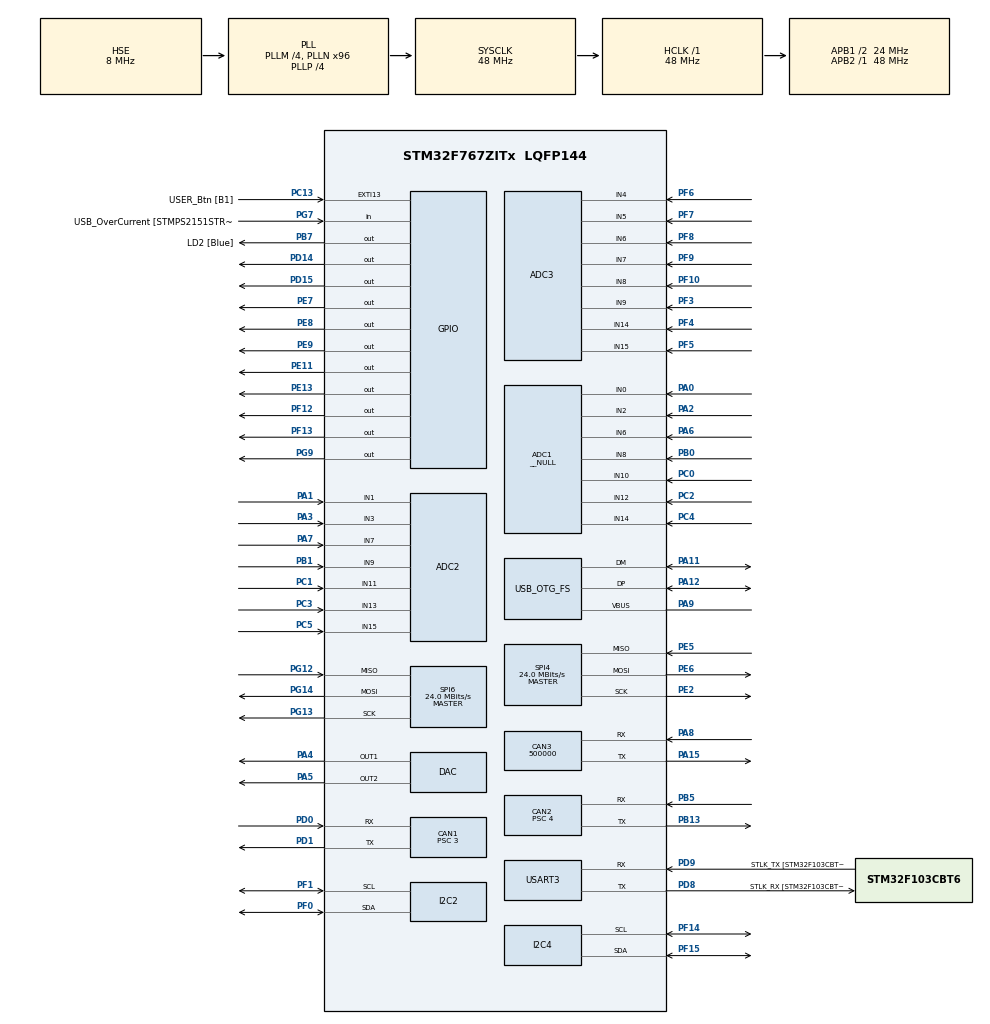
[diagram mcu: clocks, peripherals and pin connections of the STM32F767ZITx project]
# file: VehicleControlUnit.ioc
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ADC1.Channel-2\#ChannelRegularConversion=ADC_CHANNEL_0
ADC1.Channel-3\#ChannelRegularConversion=ADC_CHANNEL_2
ADC1.Channel-4\#ChannelRegularConversion=ADC_CHANNEL_6
ADC1.Channel-5\#ChannelRegularConversion=ADC_CHANNEL_8
ADC1.Channel-6\#ChannelRegularConversion=ADC_CHANNEL_10
ADC1.Channel-7\#ChannelRegularConversion=ADC_CHANNEL_12
ADC1.Channel-8\#ChannelRegularConversion=ADC_CHANNEL_12
ADC1.ClockPrescaler=ADC_CLOCK_SYNC_PCLK_DIV4
ADC1.ContinuousConvMode=DISABLE
ADC1.DMAContinuousRequests=ENABLE
ADC1.EOCSelection=ADC_EOC_SEQ_CONV
ADC1.ExternalTrigConv=ADC_EXTERNALTRIGCONV_T2_TRGO
ADC1.Mode=__NULL
ADC1.NbrOfConversion=7
ADC1.NbrOfConversionFlag=1
ADC1.Rank-2\#ChannelRegularConversion=1
ADC1.Rank-3\#ChannelRegularConversion=2
ADC1.Rank-4\#ChannelRegularConversion=3
ADC1.Rank-5\#ChannelRegularConversion=4
ADC1.Rank-6\#ChannelRegularConversion=5
ADC1.Rank-7\#ChannelRegularConversion=6
ADC1.Rank-8\#ChannelRegularConversion=7
ADC1.SamplingTime-2\#ChannelRegularConversion=ADC_SAMPLETIME_28CYCLES
ADC1.SamplingTime-3\#ChannelRegularConversion=ADC_SAMPLETIME_28CYCLES
ADC1.SamplingTime-4\#ChannelRegularConversion=ADC_SAMPLETIME_28CYCLES
ADC1.SamplingTime-5\#ChannelRegularConversion=ADC_SAMPLETIME_28CYCLES
ADC1.SamplingTime-6\#ChannelRegularConversion=ADC_SAMPLETIME_28CYCLES
ADC1.SamplingTime-7\#ChannelRegularConversion=ADC_SAMPLETIME_28CYCLES
ADC1.SamplingTime-8\#ChannelRegularConversion=ADC_SAMPLETIME_28CYCLES
ADC1.master=1
ADC2.Channel-2\#ChannelRegularConversion=ADC_CHANNEL_1
ADC2.Channel-3\#ChannelRegularConversion=ADC_CHANNEL_3
ADC2.Channel-4\#ChannelRegularConversion=ADC_CHANNEL_7
ADC2.Channel-5\#ChannelRegularConversion=ADC_CHANNEL_9
ADC2.Channel-6\#ChannelRegularConversion=ADC_CHANNEL_11
ADC2.Channel-7\#ChannelRegularConversion=ADC_CHANNEL_13
ADC2.Channel-8\#ChannelRegularConversion=ADC_CHANNEL_15
ADC2.ClockPrescaler=ADC_CLOCK_SYNC_PCLK_DIV4
ADC2.ContinuousConvMode=DISABLE
ADC2.DMAContinuousRequests=ENABLE
ADC2.EOCSelection=ADC_EOC_SEQ_CONV
ADC2.ExternalTrigConv=ADC_EXTERNALTRIGCONV_T2_TRGO
ADC2.NbrOfConversion=7
ADC2.NbrOfConversionFlag=1
ADC2.Rank-2\#ChannelRegularConversion=1
ADC2.Rank-3\#ChannelRegularConversion=2
ADC2.Rank-4\#ChannelRegularConversion=3
ADC2.Rank-5\#ChannelRegularConversion=4
ADC2.Rank-6\#ChannelRegularConversion=5
ADC2.Rank-7\#ChannelRegularConversion=6
ADC2.Rank-8\#ChannelRegularConversion=7
ADC2.SamplingTime-2\#ChannelRegularConversion=ADC_SAMPLETIME_28CYCLES
ADC2.SamplingTime-3\#ChannelRegularConversion=ADC_SAMPLETIME_28CYCLES
ADC2.SamplingTime-4\#ChannelRegularConversion=ADC_SAMPLETIME_28CYCLES
ADC2.SamplingTime-5\#ChannelRegularConversion=ADC_SAMPLETIME_28CYCLES
ADC2.SamplingTime-6\#ChannelRegularConversion=ADC_SAMPLETIME_28CYCLES
ADC2.SamplingTime-7\#ChannelRegularConversion=ADC_SAMPLETIME_28CYCLES
ADC2.SamplingTime-8\#ChannelRegularConversion=ADC_SAMPLETIME_28CYCLES
ADC3.Channel-10\#ChannelRegularConversion=ADC_CHANNEL_14
ADC3.Channel-11\#ChannelRegularConversion=ADC_CHANNEL_15
ADC3.Channel-4\#ChannelRegularConversion=ADC_CHANNEL_4
ADC3.Channel-5\#ChannelRegularConversion=ADC_CHANNEL_5
ADC3.Channel-6\#ChannelRegularConversion=ADC_CHANNEL_6
ADC3.Channel-7\#ChannelRegularConversion=ADC_CHANNEL_7
ADC3.Channel-8\#ChannelRegularConversion=ADC_CHANNEL_8
ADC3.Channel-9\#ChannelRegularConversion=ADC_CHANNEL_9
ADC3.ClockPrescaler=ADC_CLOCK_SYNC_PCLK_DIV4
ADC3.DMAContinuousRequests=ENABLE
ADC3.ExternalTrigConv=ADC_EXTERNALTRIGCONV_T2_TRGO
ADC3.NbrOfConversion=8
ADC3.NbrOfConversionFlag=1
ADC3.Rank-10\#ChannelRegularConversion=7
ADC3.Rank-11\#ChannelRegularConversion=8
ADC3.Rank-4\#ChannelRegularConversion=1
ADC3.Rank-5\#ChannelRegularConversion=2
ADC3.Rank-6\#ChannelRegularConversion=3
ADC3.Rank-7\#ChannelRegularConversion=4
ADC3.Rank-8\#ChannelRegularConversion=5
ADC3.Rank-9\#ChannelRegularConversion=6
ADC3.SamplingTime-10\#ChannelRegularConversion=ADC_SAMPLETIME_28CYCLES
ADC3.SamplingTime-11\#ChannelRegularConversion=ADC_SAMPLETIME_28CYCLES
ADC3.SamplingTime-4\#ChannelRegularConversion=ADC_SAMPLETIME_28CYCLES
ADC3.SamplingTime-5\#ChannelRegularConversion=ADC_SAMPLETIME_28CYCLES
ADC3.SamplingTime-6\#ChannelRegularConversion=ADC_SAMPLETIME_28CYCLES
ADC3.SamplingTime-7\#ChannelRegularConversion=ADC_SAMPLETIME_28CYCLES
ADC3.SamplingTime-8\#ChannelRegularConversion=ADC_SAMPLETIME_28CYCLES
ADC3.SamplingTime-9\#ChannelRegularConversion=ADC_SAMPLETIME_28CYCLES
CAN1.BS1=CAN_BS1_13TQ
CAN1.BS2=CAN_BS2_2TQ
CAN1.CalculateBaudRate=500000
CAN1.CalculateTimeBit=2000
CAN1.CalculateTimeQuantum=125.0
CAN1.Prescaler=3
CAN2.BS1=CAN_BS1_10TQ
CAN2.CalculateBaudRate=500000
CAN2.CalculateTimeBit=2000
CAN2.CalculateTimeQuantum=166.66666666666666
CAN2.Prescaler=4
CAN3.CalculateBaudRate=500000
CAN3.CalculateTimeBit=2000
CAN3.CalculateTimeQuantum=666.6666666666666
CORTEX_M7.CPU_DCache=Disabled
CORTEX_M7.CPU_ICache=Disabled
DAC.DAC_Trigger=DAC_TRIGGER_T2_TRGO
DAC.DAC_Trigger2=DAC_TRIGGER_T2_TRGO
Dma.ADC1.0.Direction=DMA_PERIPH_TO_MEMORY
Dma.ADC1.0.FIFOMode=DMA_FIFOMODE_DISABLE
Dma.ADC1.0.Instance=DMA2_Stream0
Dma.ADC1.0.MemDataAlignment=DMA_MDATAALIGN_WORD
Dma.ADC1.0.MemInc=DMA_MINC_ENABLE
Dma.ADC1.0.Mode=DMA_CIRCULAR
Dma.ADC1.0.PeriphDataAlignment=DMA_PDATAALIGN_WORD
Dma.ADC1.0.PeriphInc=DMA_PINC_DISABLE
Dma.ADC1.0.Priority=DMA_PRIORITY_LOW
Dma.ADC2.1.Direction=DMA_PERIPH_TO_MEMORY
Dma.ADC2.1.FIFOMode=DMA_FIFOMODE_DISABLE
Dma.ADC2.1.Instance=DMA2_Stream2
Dma.ADC2.1.MemDataAlignment=DMA_MDATAALIGN_WORD
Dma.ADC2.1.MemInc=DMA_MINC_ENABLE
Dma.ADC2.1.Mode=DMA_CIRCULAR
Dma.ADC2.1.PeriphDataAlignment=DMA_PDATAALIGN_WORD
Dma.ADC2.1.PeriphInc=DMA_PINC_DISABLE
Dma.ADC2.1.Priority=DMA_PRIORITY_LOW
Dma.ADC3.2.Direction=DMA_PERIPH_TO_MEMORY
Dma.ADC3.2.FIFOMode=DMA_FIFOMODE_DISABLE
Dma.ADC3.2.Instance=DMA2_Stream1
Dma.ADC3.2.MemDataAlignment=DMA_MDATAALIGN_WORD
Dma.ADC3.2.MemInc=DMA_MINC_ENABLE
Dma.ADC3.2.Mode=DMA_CIRCULAR
Dma.ADC3.2.PeriphDataAlignment=DMA_PDATAALIGN_WORD
Dma.ADC3.2.PeriphInc=DMA_PINC_DISABLE
Dma.ADC3.2.Priority=DMA_PRIORITY_LOW
Dma.DAC1.3.Direction=DMA_MEMORY_TO_PERIPH
Dma.DAC1.3.FIFOMode=DMA_FIFOMODE_DISABLE
Dma.DAC1.3.Instance=DMA1_Stream5
Dma.DAC1.3.MemDataAlignment=DMA_MDATAALIGN_HALFWORD
Dma.DAC1.3.MemInc=DMA_MINC_ENABLE
Dma.DAC1.3.Mode=DMA_CIRCULAR
Dma.DAC1.3.PeriphDataAlignment=DMA_PDATAALIGN_HALFWORD
Dma.DAC1.3.PeriphInc=DMA_PINC_DISABLE
Dma.DAC1.3.Priority=DMA_PRIORITY_LOW
Dma.DAC2.4.Direction=DMA_MEMORY_TO_PERIPH
Dma.DAC2.4.FIFOMode=DMA_FIFOMODE_DISABLE
Dma.DAC2.4.Instance=DMA1_Stream6
Dma.DAC2.4.MemDataAlignment=DMA_MDATAALIGN_HALFWORD
Dma.DAC2.4.MemInc=DMA_MINC_ENABLE
Dma.DAC2.4.Mode=DMA_CIRCULAR
Dma.DAC2.4.PeriphDataAlignment=DMA_PDATAALIGN_HALFWORD
Dma.DAC2.4.PeriphInc=DMA_PINC_DISABLE
Dma.DAC2.4.Priority=DMA_PRIORITY_LOW
Dma.Request0=ADC1
Dma.Request1=ADC2
Dma.Request2=ADC3
Dma.Request3=DAC1
Dma.Request4=DAC2
FREERTOS.Tasks01=defaultTask,24,128,StartDefaultTask,Default,NULL,Dynamic,NULL,NULL
I2C2.Timing=0x00506682
I2C4.Timing=0x00506682
Mcu.Family=STM32F7
Mcu.Name=STM32F767ZITx
Mcu.Package=LQFP144
NVIC.CAN1_RX0_IRQn=true\:5\:0\:false\:false\:true\:true\:true\:true\:true
NVIC.CAN2_RX0_IRQn=true\:5\:0\:false\:false\:true\:true\:true\:true\:true
NVIC.DMA1_Stream5_IRQn=true\:5\:0\:false\:false\:true\:true\:false\:true\:true
NVIC.DMA1_Stream6_IRQn=true\:5\:0\:false\:false\:true\:true\:false\:true\:true
NVIC.DMA2_Stream0_IRQn=true\:5\:0\:false\:false\:true\:true\:false\:true\:true
NVIC.DMA2_Stream1_IRQn=true\:5\:0\:false\:false\:true\:true\:false\:true\:true
NVIC.DMA2_Stream2_IRQn=true\:5\:0\:false\:false\:true\:true\:false\:true\:true
NVIC.OTG_FS_IRQn=true\:5\:0\:false\:false\:true\:true\:false\:true\:true
NVIC.PriorityGroup=NVIC_PRIORITYGROUP_4
NVIC.TIM2_IRQn=true\:5\:0\:false\:false\:true\:true\:true\:true\:true
NVIC.USART3_IRQn=true\:5\:0\:false\:false\:true\:true\:true\:true\:true
PA0/WKUP.Signal=ADCx_IN0
PA1.Signal=ADCx_IN1
PA11.Mode=Device_Only
PA11.Signal=USB_OTG_FS_DM
PA12.Mode=Device_Only
PA12.Signal=USB_OTG_FS_DP
PA13.GPIO_Label=TMS
PA13.Mode=Trace_Asynchronous_SW
PA13.Signal=SYS_JTMS-SWDIO
PA14.GPIO_Label=TCK
PA14.Mode=Trace_Asynchronous_SW
PA14.Signal=SYS_JTCK-SWCLK
PA15.Mode=CAN_Activate
PA15.Signal=CAN3_TX
PA2.Signal=ADCx_IN2
PA3.Signal=ADCx_IN3
PA4.Signal=COMP_DAC1_group
PA5.Signal=COMP_DAC2_group
PA6.Signal=ADCx_IN6
PA7.Signal=ADCx_IN7
PA8.Mode=CAN_Activate
PA8.Signal=CAN3_RX
PA9.Mode=Activate_VBUS
PA9.Signal=USB_OTG_FS_VBUS
PB0.Signal=ADCx_IN8
PB1.Signal=ADCx_IN9
PB13.Mode=CAN_Activate
PB13.Signal=CAN2_TX
PB3.Mode=Trace_Asynchronous_SW
PB3.Signal=SYS_JTDO-SWO
PB5.Mode=CAN_Activate
PB5.Signal=CAN2_RX
PB7.GPIO_Label=LD2 [Blue]
PB7.Signal=GPIO_Output
PB8.Signal=SDMMC1_D4
PB9.Signal=SDMMC1_D5
PC0.Signal=ADCx_IN10
PC1.Signal=ADCx_IN11
PC10.Signal=SDMMC1_D2
PC11.Signal=SDMMC1_D3
PC12.Signal=SDMMC1_CK
PC13.GPIO_Label=USER_Btn [B1]
PC13.Signal=GPXTI13
PC14/OSC32_IN.Mode=LSE-External-Oscillator
PC14/OSC32_IN.Signal=RCC_OSC32_IN
PC15/OSC32_OUT.Mode=LSE-External-Oscillator
PC15/OSC32_OUT.Signal=RCC_OSC32_OUT
PC2.Signal=ADCx_IN12
PC3.Signal=ADCx_IN13
PC4.Signal=ADCx_IN14
PC5.Signal=ADCx_IN15
PC6.Signal=SDMMC1_D6
PC7.Signal=SDMMC1_D7
PC8.Signal=SDMMC1_D0
PC9.Signal=SDMMC1_D1
PD0.Mode=CAN_Activate
PD0.Signal=CAN1_RX
PD1.Mode=CAN_Activate
PD1.Signal=CAN1_TX
PD14.Signal=GPIO_Output
PD15.Signal=GPIO_Output
PD2.Signal=SDMMC1_CMD
PD8.GPIO_Label=STLK_RX [STM32F103CBT6_PA3]
PD8.Mode=Asynchronous
PD8.Signal=USART3_TX
PD9.GPIO_Label=STLK_TX [STM32F103CBT6_PA2]
PD9.Mode=Asynchronous
PD9.Signal=USART3_RX
PE11.Signal=GPIO_Output
PE13.Signal=GPIO_Output
PE2.Mode=Full_Duplex_Master
PE2.Signal=SPI4_SCK
PE5.Mode=Full_Duplex_Master
PE5.Signal=SPI4_MISO
PE6.Mode=Full_Duplex_Master
PE6.Signal=SPI4_MOSI
PE7.Signal=GPIO_Output
PE8.Signal=GPIO_Output
PE9.Signal=GPIO_Output
PF0.Mode=I2C
PF0.Signal=I2C2_SDA
PF1.Mode=I2C
PF1.Signal=I2C2_SCL
PF10.Mode=IN8
PF10.Signal=ADC3_IN8
PF12.Signal=GPIO_Output
PF13.Signal=GPIO_Output
PF14.Mode=I2C
PF14.Signal=I2C4_SCL
PF15.Mode=I2C
PF15.Signal=I2C4_SDA
PF3.Mode=IN9
PF3.Signal=ADC3_IN9
PF4.Mode=IN14
PF4.Signal=ADC3_IN14
PF5.Mode=IN15
PF5.Signal=ADC3_IN15
PF6.Mode=IN4
PF6.Signal=ADC3_IN4
PF7.Mode=IN5
PF7.Signal=ADC3_IN5
PF8.Mode=IN6
PF8.Signal=ADC3_IN6
PF9.Mode=IN7
PF9.Signal=ADC3_IN7
PG12.Mode=Full_Duplex_Master
PG12.Signal=SPI6_MISO
PG13.Mode=Full_Duplex_Master
PG13.Signal=SPI6_SCK
PG14.Mode=Full_Duplex_Master
PG14.Signal=SPI6_MOSI
PG7.GPIO_Label=USB_OverCurrent [STMPS2151STR_FAULT]
PG7.Signal=GPIO_Input
PG9.Signal=GPIO_Output
PH0/OSC_IN.GPIO_Label=MCO [STM32F103CBT6_PA8]
PH0/OSC_IN.Mode=HSE-External-Clock-Source
PH0/OSC_IN.Signal=RCC_OSC_IN
PH1/OSC_OUT.Mode=HSE-External-Clock-Source
PH1/OSC_OUT.Signal=RCC_OSC_OUT
ProjectManager.HeapSize=0x200
ProjectManager.StackSize=0x400
ProjectManager.TargetToolchain=STM32CubeIDE
RCC.48MHZClocksFreq_Value=24000000
RCC.AHBFreq_Value=48000000
RCC.APB1CLKDivider=RCC_HCLK_DIV2
RCC.APB1Freq_Value=24000000
RCC.APB1TimFreq_Value=48000000
RCC.APB2Freq_Value=48000000
RCC.APB2TimFreq_Value=48000000
RCC.CortexFreq_Value=48000000
RCC.HCLKFreq_Value=48000000
RCC.HSE_VALUE=8000000
RCC.HSI_VALUE=16000000
RCC.PLLM=4
RCC.PLLMUL=RCC_PLL_MUL9
RCC.PLLN=96
RCC.PLLP=RCC_PLLP_DIV4
RCC.PLLQ=4
RCC.PLLSourceVirtual=RCC_PLLSOURCE_HSE
RCC.PRESCALERUSB=RCC_USBCLKSOURCE_PLL_DIV1_5
RCC.SYSCLKFreq_VALUE=48000000
RCC.SYSCLKSource=RCC_SYSCLKSOURCE_PLLCLK
RCC.SYSCLKSourceVirtual=RCC_SYSCLKSOURCE_PLLCLK
RCC.USBFreq_Value=48000000
RCC.VCOOutputFreq_Value=192000000
SH.ADCx_IN0.0=ADC1_IN0,IN0
SH.ADCx_IN1.0=ADC2_IN1,IN1
SH.ADCx_IN10.0=ADC1_IN10,IN10
SH.ADCx_IN11.0=ADC2_IN11,IN11
SH.ADCx_IN12.0=ADC1_IN12,IN12
SH.ADCx_IN13.0=ADC2_IN13,IN13
SH.ADCx_IN14.0=ADC1_IN14,IN14
SH.ADCx_IN15.0=ADC2_IN15,IN15
SH.ADCx_IN2.0=ADC1_IN2,IN2
SH.ADCx_IN3.0=ADC2_IN3,IN3
SH.ADCx_IN6.0=ADC1_IN6,IN6
SH.ADCx_IN7.0=ADC2_IN7,IN7
SH.ADCx_IN8.0=ADC1_IN8,IN8
SH.ADCx_IN9.0=ADC2_IN9,IN9
SH.COMP_DAC1_group.0=DAC_OUT1,DAC_OUT1
SH.COMP_DAC2_group.0=DAC_OUT2,DAC_OUT2
SPI4.CalculateBaudRate=24.0 MBits/s
SPI4.Direction=SPI_DIRECTION_2LINES
SPI4.Mode=SPI_MODE_MASTER
SPI4.VirtualType=VM_MASTER
SPI6.CalculateBaudRate=24.0 MBits/s
SPI6.Direction=SPI_DIRECTION_2LINES
SPI6.Mode=SPI_MODE_MASTER
SPI6.VirtualType=VM_MASTER
TIM1.Period=999
TIM1.Prescaler=47999
TIM2.Period=479999
TIM2.Prescaler=0
TIM2.TIM_MasterOutputTrigger=TIM_TRGO_UPDATE
USART3.VirtualMode-Asynchronous=VM_ASYNC
USB_DEVICE.CLASS_NAME_FS=CDC
USB_DEVICE.VirtualMode-CDC_FS=Cdc
USB_DEVICE.VirtualModeFS=Cdc_FS
USB_OTG_FS.VirtualMode=Device_Only
VP_FREERTOS_VS_CMSIS_V2.Mode=CMSIS_V2
VP_TIM1_VS_ClockSourceINT.Mode=Internal
VP_TIM2_VS_ClockSourceINT.Mode=Internal
VP_USB_DEVICE_VS_USB_DEVICE_CDC_FS.Mode=CDC_FS
board=NUCLEO-F767ZI

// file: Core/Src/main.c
/* USER CODE BEGIN Header */
/**
  ******************************************************************************
  * @file           : main.c
  * @brief          : Main program body
  ******************************************************************************
  * @attention
  *
  * Copyright (c) 2024 STMicroelectronics.
  * All rights reserved.
  *
  * This software is licensed under terms that can be found in the LICENSE file
  * in the root directory of this software component.
  * If no LICENSE file comes with this software, it is provided AS-IS.
  *
  ******************************************************************************
  */
/* USER CODE END Header */
#include "main.h"
#include "cmsis_os.h"
#include "usb_device.h"

/* USER CODE BEGIN Includes */
#include "../Inc/Files/can1_dbc.h"
#define INVERTER_TEST_DBC_IMPLEMENTATION  // Define DBC data in this file only
#include "../Inc/Files/inverter_test_dbc.h"

#define CANBUS_1_DBC_IMPLEMENTATION  // Define DBC data in this file only
#include "../Inc/Files/canbus_1_dbc.h"
#include "../Inc/Scheduler/Scheduler.h"
#include "../Inc/Sensors/AnalogSensor.h"
#include "../Inc/Systems/Comms/Can/Can.h"
#include "../Inc/Systems/Comms/Can/CANCommsSystem.h"
#include "../Inc/Systems/Controller/Apps.h"
#include "../Inc/Systems/Controller/BrakeSystemControl.h"
#include "../Inc/Systems/Controller/RTD.h"
#include "../Inc/Systems/Controller/TorqueControl.h"
#include "../Inc/Systems/External/Inverter.h"
#include "../Inc/Systems/Monitor/AppsMonitor.h"
#include "../Inc/Systems/Monitor/BrakePolice.h"
#include "../Inc/Systems/Monitor/RTDMonitor.h"
#include "../Inc/Systems/Monitor/TorquePolice.h"
#include "../Inc/Utils/Constants.h"
#include "../Inc/Utils/MessageFormat.h"
#include "../Inc/Utils/Telemetry.h"

#ifndef TEST_MODE
#include "stm32f7xx_hal_adc.h"
#include "stm32f7xx_it.h"
#endif
/* USER CODE END Includes */

/* USER CODE BEGIN PM */
#ifndef TEST_MODE
/* USER CODE END PM */

ADC_HandleTypeDef hadc1;
ADC_HandleTypeDef hadc2;
ADC_HandleTypeDef hadc3;
DMA_HandleTypeDef hdma_adc1;
DMA_HandleTypeDef hdma_adc2;
DMA_HandleTypeDef hdma_adc3;

CAN_HandleTypeDef hcan1;
CAN_HandleTypeDef hcan2;
CAN_HandleTypeDef hcan3;

DAC_HandleTypeDef hdac;
DMA_HandleTypeDef hdma_dac1;
DMA_HandleTypeDef hdma_dac2;
DMA_HandleTypeDef hdma_usart3_tx;

I2C_HandleTypeDef hi2c2;
I2C_HandleTypeDef hi2c4;

SPI_HandleTypeDef hspi4;
SPI_HandleTypeDef hspi6;

TIM_HandleTypeDef htim1;
TIM_HandleTypeDef htim2;

UART_HandleTypeDef huart3;

/* Definitions for defaultTask */
osThreadId_t defaultTaskHandle;
const osThreadAttr_t defaultTask_attributes = {
  .name = "defaultTask",
  .stack_size = 128 * 4,
  .priority = (osPriority_t) osPriorityNormal,
};
/* USER CODE BEGIN PV */
// New CAN Communications Systems (alongside existing CAN)
CANCommsSystem can1_comms;
CANCommsSystem can2_comms;
Updateable telemetryUpdateable;
/* USER CODE END PV */

void SystemClock_Config(void);
static void MX_GPIO_Init(void);
static void MX_DMA_Init(void);
static void MX_TIM1_Init(void);
static void MX_ADC1_Init(void);
static void MX_ADC2_Init(void);
static void MX_ADC3_Init(void);
static void MX_CAN1_Init(void);
static void MX_CAN2_Init(void);
static void MX_USART3_UART_Init(void);
static void MX_TIM2_Init(void);
static void MX_DAC_Init(void);
static void MX_CAN3_Init(void);
static void MX_I2C2_Init(void);
static void MX_I2C4_Init(void);
static void MX_SPI4_Init(void);
static void MX_SPI6_Init(void);
void StartDefaultTask(void *argument);

/* USER CODE BEGIN PFP */
// CAN message handler for Inverter system
//void inverter_can_handler(void* system, CAN_Message* message);
void send_test_inverter_messages(void);

// UART configuration listener
void initUartConfigListener(void);
int telemetryUpdateableCallback(Updateable* self);
#endif
/* USER CODE END PFP */

/* USER CODE BEGIN 0 */
uint32_t adc1_buffer[ADC1_CHANNEL_SIZE];
uint32_t adc2_buffer[ADC2_CHANNEL_SIZE];
uint32_t adc3_buffer[ADC3_CHANNEL_SIZE];
uint32_t dac1_buffer[DAC1_BUFFER_SIZE];
uint32_t dac2_buffer[DAC2_BUFFER_SIZE];
uint8_t digital_out_buffer[NUM_DIGITAL_OUTPUTS];
uint8_t digital_in_buffer[NUM_DIGITAL_INPUTS];

/* USER CODE END 0 */

int main(void)
{

  /* USER CODE BEGIN 1 */

  #ifndef TEST_MODE

  /* USER CODE END 1 */

  /* MCU Configuration--------------------------------------------------------*/

  /* Reset of all peripherals, Initializes the Flash interface and the Systick. */
  HAL_Init();

  /* Configure the system clock */
  SystemClock_Config();

  /* Initialize all configured peripherals */
  MX_GPIO_Init();
  MX_DMA_Init();
  MX_TIM1_Init();
  MX_ADC1_Init();
  MX_ADC2_Init();
  MX_ADC3_Init();
  MX_CAN1_Init();
  MX_CAN2_Init();
  MX_USART3_UART_Init();
  MX_TIM2_Init();
  MX_DAC_Init();
  MX_CAN3_Init();
  MX_I2C2_Init();
  MX_I2C4_Init();
  MX_SPI4_Init();
  MX_SPI6_Init();
  /* USER CODE BEGIN 2 */

  // Clear the screen
  // //printf("\033[2J\033[1;1H");
  // //printf("Welcome to VCU!!!\r\n");
  if (init_CANBus(CAN_1) != 0) {
    // //printf("CAN1 init failed\r\n");
  }

  // Init Telemetry
  initTelemetry();

  // Scheduler-based telemetry processor
  initUpdateable(&telemetryUpdateable, "TelemetrySystem", 10, SYSTEM, NULL);
  telemetryUpdateable.update = telemetryUpdateableCallback;
  telemetryUpdateable.enable(&telemetryUpdateable);

  // Initialize New CAN Communications Systems (alongside existing CAN)
  if (initCANCommsSystem(&can1_comms, "CAN1_COMMS", 10, CAN_1) != 0) {
    sendMessage("INIT", MSG_ERROR, "CANCommsSystem CAN1 initialization failed");
  } else {
    sendMessage("INIT", MSG_SYSTEM_STATUS, "CANCommsSystem CAN1 initialized successfully");

    // Load the enhanced DBC database
    if (loadCANDatabase(&can1_comms, canbus_1_dbc) != 0) {
      sendMessage("INIT", MSG_ERROR, "CAN1 DBC database load failed");
    } else {
      sendMessage("INIT", MSG_SYSTEM_STATUS, "CAN1 DBC database loaded successfully");
    }
  }

  // Initialize CAN2 system as well
  if (initCANCommsSystem(&can2_comms, "CAN2_COMMS", 10, CAN_2) != 0) {
    sendMessage("INIT", MSG_ERROR, "CANCommsSystem CAN2 initialization failed");
  } else {
    sendMessage("INIT", MSG_SYSTEM_STATUS, "CANCommsSystem CAN2 initialized successfully");

    // Load the same DBC database for CAN2 (can be different if needed)
    if (loadCANDatabase(&can2_comms, canbus_1_dbc) != 0) {
      sendMessage("INIT", MSG_ERROR, "CAN2 DBC database load failed");
    } else {
      sendMessage("INIT", MSG_SYSTEM_STATUS, "CAN2 DBC database loaded successfully");
    }
  }

  // Begin ADC DMA
  if(HAL_ADC_Start_DMA(&hadc1, (uint32_t*)adc1_buffer, 7) != HAL_OK) {
	  Error_Handler();
  }

  if(HAL_ADC_Start_DMA(&hadc2, (uint32_t*)adc2_buffer, 7) != HAL_OK) {
    Error_Handler();
  }

  if(HAL_ADC_Start_DMA(&hadc3, (uint32_t*)adc3_buffer, 8) != HAL_OK) {
    Error_Handler();
  }

  // Begin DAC DMA
  if(HAL_DAC_Start_DMA(&hdac, DAC_CHANNEL_1, (uint32_t*)dac1_buffer, DAC1_BUFFER_SIZE, DAC_ALIGN_12B_R) != HAL_OK) {
    Error_Handler();
  }

  __HAL_UART_ENABLE_IT(&huart3, UART_IT_RXNE);
  initUartConfigListener();

  uint32_t multi_mode = (ADC123_COMMON->CCR & ADC_CCR_MULTI);
  (void)multi_mode;  // Suppress unused variable warning
  //printf("ADC Multi-mode: 0x%08lX\r\n", multi_mode);

  #endif

  // Add a message to the CAN message list
  CAN_Signal_Template signals[8] = {
    { .name = "VDD", .start_bit = 0, .length = 8, .endian = 0, .isSigned = 0, .scale = 0.1, .offset = 0, .min = 0, .max = 255, .unit = "voltage", .reciever = "reciever" },
    { .name = "Char 2", .start_bit = 8, .length = 8, .endian = 0, .isSigned = 0, .scale = 1, .offset = 0, .min = 0, .max = 255, .unit = "unit", .reciever = "reciever" },
    { .name = "Char 3", .start_bit = 16, .length = 8, .endian = 0, .isSigned = 0, .scale = 1, .offset = 0, .min = 0, .max = 255, .unit = "unit", .reciever = "reciever" },
    { .name = "Char 4", .start_bit = 24, .length = 8, .endian = 0, .isSigned = 0, .scale = 1, .offset = 0, .min = 0, .max = 255, .unit = "unit", .reciever = "reciever" },
    { .name = "Char 5", .start_bit = 32, .length = 8, .endian = 0, .isSigned = 0, .scale = 1, .offset = 0, .min = 0, .max = 255, .unit = "unit", .reciever = "reciever" },
    { .name = "Char 6", .start_bit = 40, .length = 8, .endian = 0, .isSigned = 0, .scale = 1, .offset = 0, .min = 0, .max = 255, .unit = "unit", .reciever = "reciever" },
    { .name = "Char 7", .start_bit = 48, .length = 8, .endian = 0, .isSigned = 0, .scale = 1, .offset = 0, .min = 0, .max = 255, .unit = "unit", .reciever = "reciever" },
    { .name = "Char 8", .start_bit = 56, .length = 8, .endian = 0, .isSigned = 0, .scale = 1, .offset = 0, .min = 0, .max = 255, .unit = "unit", .reciever = "reciever" }
  };

  add_message_lop(CAN_1, 0x123, 8, 0, 0, "Message 1", "AD3", 8, signals);

  add_message_lop(CAN_1, 0x124, 8, 0, 0, "Message 2", "VCU", 8, signals);

  // Print the CAN message list
  print_CAN_Messages_Lists();

  uint8_t txdata[8] = {0, 1, 2, 3, 4, 5, 6, 7};
  send_CAN_message(CAN_1, CAN_2A, 124, txdata, 8);

  // Make Apps Controller and Monitor
  Apps apps;
  initApps(&apps, 10, 8, 4);

  AppsMonitor am;
  initAppsMonitor(&am, &apps, 10);

  // Bind Appsmonitor to Apps
  apps.base.addMonitor((ControllerSystem*)&apps, (MonitorSystem*)&am);

  // Start the Apps Monitor
  startAppsMonitor(&am);

  // Make Break Controller and Monitor
  BrakeSystemControl bsc;
  initBrakeSystemControl(&bsc, 10, 200, 400, 1000, 10, 5, 6, 0);

  BrakePolice bp;
  initBrakePolice(&bp, &bsc, 100, 200);

  // Bind BrakePolice to BrakeSystemControl
  bsc.base.addMonitor((ControllerSystem*)&bsc, (MonitorSystem*)&bp);

  // Start the Brake Controller and Monitor
  startBrakeSystemControl(&bsc);
  startBrakePolice(&bp);

  // Make RTD Controller and Monitor
  RTD rtd;
  initRTD(&rtd, &apps, &bsc, 10, 0, 1);

  RTDMonitor rm;
  initRTDMonitor(&rm, &rtd, 10);

  // Bind RTDMonitor to RTD
  rtd.base.addMonitor((ControllerSystem*)&rtd, (MonitorSystem*)&rm);

  // Start the RTD Controller and Monitor
  startRTD(&rtd);
  startRTDMonitor(&rm);

  // Make Inverter (Rinehart PM100DX)
  Inverter inverter;
  initInverter(&inverter, &can1_comms, 10, CAN_1, 500);  // 10Hz update, CAN1 system, CAN1 bus, 500ms heartbeat timeout

  // Register Inverter for CAN messages (VCU receives inverter status messages)
//  if (registerCANReceiver(&can1_comms, "VCU_Inverter_Ext", &inverter, inverterCANMessageHandler, EXTERNAL) == 0) {
//    sendMessage("INIT", MSG_SYSTEM_STATUS, "Rinehart PM100DX Inverter registered for CAN messages");
//  } else {
//    sendMessage("INIT", MSG_WARNING, "Failed to register Inverter for CAN messages");
//  }

  // Make Torque Controller and Monitor
  TorqueControl tc;
  initTorqueControl(&tc, &apps, 10, 240);

  // Make Scheduler from updateable array
  Scheduler scheduler;

  Updateable* updateables[9];  // Increased size to include CAN systems and telemetry
  updateables[0] = &apps.base.system.updateable;
  updateables[1] = &bsc.base.system.updateable;
  updateables[2] = &rtd.base.system.updateable;
  updateables[3] = &tc.base.system.updateable;
  updateables[4] = &inverter.base.system.updateable;
  updateables[5] = &can1_comms.base.system.updateable;  // Add CAN1 system
  updateables[6] = &can2_comms.base.system.updateable;  // Add CAN2 system
  updateables[7] = &telemetryUpdateable;
  updateables[8] = NULL;

  SchedulerInit(&scheduler, updateables);

  //printf("Starting Vehicle Control Unit with FreeRTOS scheduler...\n");

  // Start the Scheduler
  SchedulerRun(&scheduler);
  /* USER CODE END 2 */

  /* Init scheduler */
  osKernelInitialize();

  /* Create the thread(s) */
  /* creation of defaultTask */
  defaultTaskHandle = osThreadNew(StartDefaultTask, NULL, &defaultTask_attributes);

  /* Start scheduler */
  osKernelStart();

  /* We should never get here as control is now taken by the scheduler */

  /* Infinite loop */
  /* USER CODE BEGIN WHILE */
  static uint32_t test_can_counter = 0;
  while (1)
  {
    //printf("ERROR: Scheduler returned unexpectedly!\n");

    // Send test CAN message every 5 seconds
    test_can_counter++;
    if (test_can_counter >= 5) {
      test_can_counter = 0;

      // Send test CAN message with incrementing data
      uint8_t test_data[8] = {0xAA, 0xBB, 0xCC, 0xDD, (uint8_t)(HAL_GetTick() & 0xFF), 0x55, 0x66, 0x77};
      send_CAN_message(CAN_1, CAN_2A, 0x123, test_data, 8);

      // NOTE: This code never runs because SchedulerRun() blocks the main loop!

      // Send another test message with different ID
      uint8_t test_data2[8] = {0x11, 0x22, 0x33, 0x44, 0x55, 0x66, 0x77, (uint8_t)((HAL_GetTick() >> 8) & 0xFF)};
      send_CAN_message(CAN_1, CAN_2A, 0x456, test_data2, 8);
    }

    HAL_Delay(1000);
    /* USER CODE END WHILE */

    /* USER CODE BEGIN 3 */
  }
  #ifndef TEST_MODE
  /* USER CODE END 3 */
}

void SystemClock_Config(void)
{
  RCC_OscInitTypeDef RCC_OscInitStruct = {0};
  RCC_ClkInitTypeDef RCC_ClkInitStruct = {0};

  /** Configure LSE Drive Capability
  */
  HAL_PWR_EnableBkUpAccess();

  /** Configure the main internal regulator output voltage
  */
  __HAL_RCC_PWR_CLK_ENABLE();
  __HAL_PWR_VOLTAGESCALING_CONFIG(PWR_REGULATOR_VOLTAGE_SCALE3);

  /** Initializes the RCC Oscillators according to the specified parameters
  * in the RCC_OscInitTypeDef structure.
  */
  RCC_OscInitStruct.OscillatorType = RCC_OSCILLATORTYPE_HSE;
  RCC_OscInitStruct.HSEState = RCC_HSE_BYPASS;
  RCC_OscInitStruct.PLL.PLLState = RCC_PLL_ON;
  RCC_OscInitStruct.PLL.PLLSource = RCC_PLLSOURCE_HSE;
  RCC_OscInitStruct.PLL.PLLM = 4;
  RCC_OscInitStruct.PLL.PLLN = 96;
  RCC_OscInitStruct.PLL.PLLP = RCC_PLLP_DIV4;
  RCC_OscInitStruct.PLL.PLLQ = 4;
  RCC_OscInitStruct.PLL.PLLR = 2;
  if (HAL_RCC_OscConfig(&RCC_OscInitStruct) != HAL_OK)
  {
    Error_Handler();
  }

  /** Initializes the CPU, AHB and APB buses clocks
  */
  RCC_ClkInitStruct.ClockType = RCC_CLOCKTYPE_HCLK|RCC_CLOCKTYPE_SYSCLK
                              |RCC_CLOCKTYPE_PCLK1|RCC_CLOCKTYPE_PCLK2;
  RCC_ClkInitStruct.SYSCLKSource = RCC_SYSCLKSOURCE_PLLCLK;
  RCC_ClkInitStruct.AHBCLKDivider = RCC_SYSCLK_DIV1;
  RCC_ClkInitStruct.APB1CLKDivider = RCC_HCLK_DIV2;
  RCC_ClkInitStruct.APB2CLKDivider = RCC_HCLK_DIV1;

  if (HAL_RCC_ClockConfig(&RCC_ClkInitStruct, FLASH_LATENCY_1) != HAL_OK)
  {
    Error_Handler();
  }
}

static void MX_ADC1_Init(void)
{

  ADC_ChannelConfTypeDef sConfig = {0};

  /** Configure the global features of the ADC (Clock, Resolution, Data Alignment and number of conversion)
  */
  hadc1.Instance = ADC1;
  hadc1.Init.ClockPrescaler = ADC_CLOCK_SYNC_PCLK_DIV4;
  hadc1.Init.Resolution = ADC_RESOLUTION_12B;
  hadc1.Init.ScanConvMode = ADC_SCAN_ENABLE;
  hadc1.Init.ContinuousConvMode = DISABLE;
  hadc1.Init.DiscontinuousConvMode = DISABLE;
  hadc1.Init.ExternalTrigConvEdge = ADC_EXTERNALTRIGCONVEDGE_RISING;
  hadc1.Init.ExternalTrigConv = ADC_EXTERNALTRIGCONV_T2_TRGO;
  hadc1.Init.DataAlign = ADC_DATAALIGN_RIGHT;
  hadc1.Init.NbrOfConversion = 7;
  hadc1.Init.DMAContinuousRequests = ENABLE;
  hadc1.Init.EOCSelection = ADC_EOC_SEQ_CONV;
  if (HAL_ADC_Init(&hadc1) != HAL_OK)
  {
    Error_Handler();
  }

  /** Configure for the selected ADC regular channel its corresponding rank in the sequencer and its sample time.
  */
  sConfig.Channel = ADC_CHANNEL_0;
  sConfig.Rank = ADC_REGULAR_RANK_1;
  sConfig.SamplingTime = ADC_SAMPLETIME_28CYCLES;
  if (HAL_ADC_ConfigChannel(&hadc1, &sConfig) != HAL_OK)
  {
    Error_Handler();
  }

  /** Configure for the selected ADC regular channel its corresponding rank in the sequencer and its sample time.
  */
  sConfig.Channel = ADC_CHANNEL_2;
  sConfig.Rank = ADC_REGULAR_RANK_2;
  if (HAL_ADC_ConfigChannel(&hadc1, &sConfig) != HAL_OK)
  {
    Error_Handler();
  }

  /** Configure for the selected ADC regular channel its corresponding rank in the sequencer and its sample time.
  */
  sConfig.Channel = ADC_CHANNEL_6;
  sConfig.Rank = ADC_REGULAR_RANK_3;
  if (HAL_ADC_ConfigChannel(&hadc1, &sConfig) != HAL_OK)
  {
    Error_Handler();
  }

  /** Configure for the selected ADC regular channel its corresponding rank in the sequencer and its sample time.
  */
  sConfig.Channel = ADC_CHANNEL_8;
  sConfig.Rank = ADC_REGULAR_RANK_4;
  if (HAL_ADC_ConfigChannel(&hadc1, &sConfig) != HAL_OK)
  {
    Error_Handler();
  }

  /** Configure for the selected ADC regular channel its corresponding rank in the sequencer and its sample time.
  */
  sConfig.Channel = ADC_CHANNEL_10;
  sConfig.Rank = ADC_REGULAR_RANK_5;
  if (HAL_ADC_ConfigChannel(&hadc1, &sConfig) != HAL_OK)
  {
    Error_Handler();
  }

  /** Configure for the selected ADC regular channel its corresponding rank in the sequencer and its sample time.
  */
  sConfig.Channel = ADC_CHANNEL_12;
  sConfig.Rank = ADC_REGULAR_RANK_6;
  if (HAL_ADC_ConfigChannel(&hadc1, &sConfig) != HAL_OK)
  {
    Error_Handler();
  }

  /** Configure for the selected ADC regular channel its corresponding rank in the sequencer and its sample time.
  */
  sConfig.Rank = ADC_REGULAR_RANK_7;
  if (HAL_ADC_ConfigChannel(&hadc1, &sConfig) != HAL_OK)
  {
    Error_Handler();
  }

}

static void MX_ADC2_Init(void)
{

  ADC_ChannelConfTypeDef sConfig = {0};

  /** Configure the global features of the ADC (Clock, Resolution, Data Alignment and number of conversion)
  */
  hadc2.Instance = ADC2;
  hadc2.Init.ClockPrescaler = ADC_CLOCK_SYNC_PCLK_DIV4;
  hadc2.Init.Resolution = ADC_RESOLUTION_12B;
  hadc2.Init.ScanConvMode = ADC_SCAN_ENABLE;
  hadc2.Init.ContinuousConvMode = DISABLE;
  hadc2.Init.DiscontinuousConvMode = DISABLE;
  hadc2.Init.ExternalTrigConvEdge = ADC_EXTERNALTRIGCONVEDGE_RISING;
  hadc2.Init.ExternalTrigConv = ADC_EXTERNALTRIGCONV_T2_TRGO;
  hadc2.Init.DataAlign = ADC_DATAALIGN_RIGHT;
  hadc2.Init.NbrOfConversion = 7;
  hadc2.Init.DMAContinuousRequests = ENABLE;
  hadc2.Init.EOCSelection = ADC_EOC_SEQ_CONV;
  if (HAL_ADC_Init(&hadc2) != HAL_OK)
  {
    Error_Handler();
  }

  /** Configure for the selected ADC regular channel its corresponding rank in the sequencer and its sample time.
  */
  sConfig.Channel = ADC_CHANNEL_1;
  sConfig.Rank = ADC_REGULAR_RANK_1;
  sConfig.SamplingTime = ADC_SAMPLETIME_28CYCLES;
  if (HAL_ADC_ConfigChannel(&hadc2, &sConfig) != HAL_OK)
  {
    Error_Handler();
  }

  /** Configure for the selected ADC regular channel its corresponding rank in the sequencer and its sample time.
  */
  sConfig.Channel = ADC_CHANNEL_3;
  sConfig.Rank = ADC_REGULAR_RANK_2;
  if (HAL_ADC_ConfigChannel(&hadc2, &sConfig) != HAL_OK)
  {
    Error_Handler();
  }

  /** Configure for the selected ADC regular channel its corresponding rank in the sequencer and its sample time.
  */
  sConfig.Channel = ADC_CHANNEL_7;
  sConfig.Rank = ADC_REGULAR_RANK_3;
  if (HAL_ADC_ConfigChannel(&hadc2, &sConfig) != HAL_OK)
  {
    Error_Handler();
  }

  /** Configure for the selected ADC regular channel its corresponding rank in the sequencer and its sample time.
  */
  sConfig.Channel = ADC_CHANNEL_9;
  sConfig.Rank = ADC_REGULAR_RANK_4;
  if (HAL_ADC_ConfigChannel(&hadc2, &sConfig) != HAL_OK)
  {
    Error_Handler();
  }

  /** Configure for the selected ADC regular channel its corresponding rank in the sequencer and its sample time.
  */
  sConfig.Channel = ADC_CHANNEL_11;
  sConfig.Rank = ADC_REGULAR_RANK_5;
  if (HAL_ADC_ConfigChannel(&hadc2, &sConfig) != HAL_OK)
  {
    Error_Handler();
  }

  /** Configure for the selected ADC regular channel its corresponding rank in the sequencer and its sample time.
  */
  sConfig.Channel = ADC_CHANNEL_13;
  sConfig.Rank = ADC_REGULAR_RANK_6;
  if (HAL_ADC_ConfigChannel(&hadc2, &sConfig) != HAL_OK)
  {
    Error_Handler();
  }

  /** Configure for the selected ADC regular channel its corresponding rank in the sequencer and its sample time.
  */
  sConfig.Channel = ADC_CHANNEL_15;
  sConfig.Rank = ADC_REGULAR_RANK_7;
  if (HAL_ADC_ConfigChannel(&hadc2, &sConfig) != HAL_OK)
  {
    Error_Handler();
  }

}

static void MX_ADC3_Init(void)
{

  ADC_ChannelConfTypeDef sConfig = {0};

  /** Configure the global features of the ADC (Clock, Resolution, Data Alignment and number of conversion)
  */
  hadc3.Instance = ADC3;
  hadc3.Init.ClockPrescaler = ADC_CLOCK_SYNC_PCLK_DIV4;
  hadc3.Init.Resolution = ADC_RESOLUTION_12B;
  hadc3.Init.ScanConvMode = ADC_SCAN_ENABLE;
  hadc3.Init.ContinuousConvMode = DISABLE;
  hadc3.Init.DiscontinuousConvMode = DISABLE;
  hadc3.Init.ExternalTrigConvEdge = ADC_EXTERNALTRIGCONVEDGE_RISING;
  hadc3.Init.ExternalTrigConv = ADC_EXTERNALTRIGCONV_T2_TRGO;
  hadc3.Init.DataAlign = ADC_DATAALIGN_RIGHT;
  hadc3.Init.NbrOfConversion = 8;
  hadc3.Init.DMAContinuousRequests = ENABLE;
  hadc3.Init.EOCSelection = ADC_EOC_SINGLE_CONV;
  if (HAL_ADC_Init(&hadc3) != HAL_OK)
  {
    Error_Handler();
  }

  /** Configure for the selected ADC regular channel its corresponding rank in the sequencer and its sample time.
  */
  sConfig.Channel = ADC_CHANNEL_4;
  sConfig.Rank = ADC_REGULAR_RANK_1;
  sConfig.SamplingTime = ADC_SAMPLETIME_28CYCLES;
  if (HAL_ADC_ConfigChannel(&hadc3, &sConfig) != HAL_OK)
  {
    Error_Handler();
  }

  /** Configure for the selected ADC regular channel its corresponding rank in the sequencer and its sample time.
  */
  sConfig.Channel = ADC_CHANNEL_5;
  sConfig.Rank = ADC_REGULAR_RANK_2;
  if (HAL_ADC_ConfigChannel(&hadc3, &sConfig) != HAL_OK)
  {
    Error_Handler();
  }

  /** Configure for the selected ADC regular channel its corresponding rank in the sequencer and its sample time.
  */
  sConfig.Channel = ADC_CHANNEL_6;
  sConfig.Rank = ADC_REGULAR_RANK_3;
  if (HAL_ADC_ConfigChannel(&hadc3, &sConfig) != HAL_OK)
  {
    Error_Handler();
  }

  /** Configure for the selected ADC regular channel its corresponding rank in the sequencer and its sample time.
  */
  sConfig.Channel = ADC_CHANNEL_7;
  sConfig.Rank = ADC_REGULAR_RANK_4;
  if (HAL_ADC_ConfigChannel(&hadc3, &sConfig) != HAL_OK)
  {
    Error_Handler();
  }

  /** Configure for the selected ADC regular channel its corresponding rank in the sequencer and its sample time.
  */
  sConfig.Channel = ADC_CHANNEL_8;
  sConfig.Rank = ADC_REGULAR_RANK_5;
  if (HAL_ADC_ConfigChannel(&hadc3, &sConfig) != HAL_OK)
  {
    Error_Handler();
  }

  /** Configure for the selected ADC regular channel its corresponding rank in the sequencer and its sample time.
  */
  sConfig.Channel = ADC_CHANNEL_9;
  sConfig.Rank = ADC_REGULAR_RANK_6;
  if (HAL_ADC_ConfigChannel(&hadc3, &sConfig) != HAL_OK)
  {
    Error_Handler();
  }

  /** Configure for the selected ADC regular channel its corresponding rank in the sequencer and its sample time.
  */
  sConfig.Channel = ADC_CHANNEL_14;
  sConfig.Rank = ADC_REGULAR_RANK_7;
  if (HAL_ADC_ConfigChannel(&hadc3, &sConfig) != HAL_OK)
  {
    Error_Handler();
  }

  /** Configure for the selected ADC regular channel its corresponding rank in the sequencer and its sample time.
  */
  sConfig.Channel = ADC_CHANNEL_15;
  sConfig.Rank = ADC_REGULAR_RANK_8;
  if (HAL_ADC_ConfigChannel(&hadc3, &sConfig) != HAL_OK)
  {
    Error_Handler();
  }

}

static void MX_CAN1_Init(void)
{

  hcan1.Instance = CAN1;
  hcan1.Init.Prescaler = 3;
  hcan1.Init.Mode = CAN_MODE_NORMAL;
  hcan1.Init.SyncJumpWidth = CAN_SJW_1TQ;
  hcan1.Init.TimeSeg1 = CAN_BS1_13TQ;
  hcan1.Init.TimeSeg2 = CAN_BS2_2TQ;
  hcan1.Init.TimeTriggeredMode = DISABLE;
  hcan1.Init.AutoBusOff = DISABLE;
  hcan1.Init.AutoWakeUp = DISABLE;
  hcan1.Init.AutoRetransmission = DISABLE;
  hcan1.Init.ReceiveFifoLocked = DISABLE;
  hcan1.Init.TransmitFifoPriority = DISABLE;
  if (HAL_CAN_Init(&hcan1) != HAL_OK)
  {
    Error_Handler();
  }
  /* USER CODE BEGIN CAN1_Init 2 */
  CAN_FilterTypeDef sFilterConfig;
  sFilterConfig.FilterBank = 0;
  sFilterConfig.FilterMode = CAN_FILTERMODE_IDMASK;
  sFilterConfig.FilterScale = CAN_FILTERSCALE_32BIT;
  sFilterConfig.FilterIdHigh = 0x0000;
  sFilterConfig.FilterIdLow = 0x0000;
  sFilterConfig.FilterMaskIdHigh = 0x0000;
  sFilterConfig.FilterMaskIdLow = 0x0000;
  sFilterConfig.FilterFIFOAssignment = CAN_RX_FIFO0;
  sFilterConfig.FilterActivation = ENABLE;
  sFilterConfig.SlaveStartFilterBank = 14;
  HAL_CAN_ConfigFilter(&hcan1, &sFilterConfig);

  // Stop CAN
  HAL_CAN_Stop(&hcan1);
  // Start CAN
  if (HAL_CAN_Start(&hcan1) != HAL_OK) {
      printf("CAN1 Start Error: ErrorCode = 0x%lX\r\n", hcan1.ErrorCode);
  } else {
      printf("CAN1 Started Successfully\r\n");
  }

  // Start IRQ for CAN Rx
  if (HAL_CAN_ActivateNotification(&hcan1, CAN_IT_RX_FIFO0_MSG_PENDING) != HAL_OK) {
  	printf("interrupt CAN1 init failed\r\n");
  } else {
      printf("CAN1 RX Interrupt Activated\r\n");
  }

  // Enable TX completion interrupts for telemetry
  if (HAL_CAN_ActivateNotification(&hcan1, CAN_IT_TX_MAILBOX_EMPTY) != HAL_OK) {
  	printf("CAN1 TX interrupt init failed\r\n");
  } else {
      printf("CAN1 TX Interrupt Activated\r\n");
  }
  /* USER CODE END CAN1_Init 2 */

}

static void MX_CAN2_Init(void)
{

  hcan2.Instance = CAN2;
  hcan2.Init.Prescaler = 4;
  hcan2.Init.Mode = CAN_MODE_NORMAL;
  hcan2.Init.SyncJumpWidth = CAN_SJW_1TQ;
  hcan2.Init.TimeSeg1 = CAN_BS1_10TQ;
  hcan2.Init.TimeSeg2 = CAN_BS2_1TQ;
  hcan2.Init.TimeTriggeredMode = DISABLE;
  hcan2.Init.AutoBusOff = DISABLE;
  hcan2.Init.AutoWakeUp = DISABLE;
  hcan2.Init.AutoRetransmission = DISABLE;
  hcan2.Init.ReceiveFifoLocked = DISABLE;
  hcan2.Init.TransmitFifoPriority = DISABLE;
  if (HAL_CAN_Init(&hcan2) != HAL_OK)
  {
    Error_Handler();
  }
  /* USER CODE BEGIN CAN2_Init 2 */
  CAN_FilterTypeDef sFilterConfig;
  sFilterConfig.FilterBank = 0;
  sFilterConfig.FilterMode = CAN_FILTERMODE_IDMASK;
  sFilterConfig.FilterScale = CAN_FILTERSCALE_32BIT;
  sFilterConfig.FilterIdHigh = 0x0000;
  sFilterConfig.FilterIdLow = 0x0000;
  sFilterConfig.FilterMaskIdHigh = 0x0000;
  sFilterConfig.FilterMaskIdLow = 0x0000;
  sFilterConfig.FilterFIFOAssignment = CAN_RX_FIFO0;
  sFilterConfig.FilterActivation = ENABLE;
  sFilterConfig.SlaveStartFilterBank = 14;
  HAL_CAN_ConfigFilter(&hcan2, &sFilterConfig);

  // Stop CAN
  HAL_CAN_Stop(&hcan2);
  // Start CAN
  if (HAL_CAN_Start(&hcan2) != HAL_OK) {
      //printf("CAN2 Start Error: ErrorCode = 0x%lX\r\n", hcan2.ErrorCode);
  }

  // Start IRQ for CAN Rx
  if (HAL_CAN_ActivateNotification(&hcan2, CAN_IT_RX_FIFO0_MSG_PENDING) != HAL_OK) {
  	//printf("interrupt CAN2 init failed\r\n");
  }

  // Enable TX completion interrupts for telemetry
  if (HAL_CAN_ActivateNotification(&hcan2, CAN_IT_TX_MAILBOX_EMPTY) != HAL_OK) {
  	//printf("CAN2 TX interrupt init failed\r\n");
  }
  /* USER CODE END CAN2_Init 2 */

}

static void MX_CAN3_Init(void)
{

  hcan3.Instance = CAN3;
  hcan3.Init.Prescaler = 16;
  hcan3.Init.Mode = CAN_MODE_NORMAL;
  hcan3.Init.SyncJumpWidth = CAN_SJW_1TQ;
  hcan3.Init.TimeSeg1 = CAN_BS1_1TQ;
  hcan3.Init.TimeSeg2 = CAN_BS2_1TQ;
  hcan3.Init.TimeTriggeredMode = DISABLE;
  hcan3.Init.AutoBusOff = DISABLE;
  hcan3.Init.AutoWakeUp = DISABLE;
  hcan3.Init.AutoRetransmission = DISABLE;
  hcan3.Init.ReceiveFifoLocked = DISABLE;
  hcan3.Init.TransmitFifoPriority = DISABLE;
  if (HAL_CAN_Init(&hcan3) != HAL_OK)
  {
    Error_Handler();
  }

}

static void MX_DAC_Init(void)
{

  DAC_ChannelConfTypeDef sConfig = {0};

  /** DAC Initialization
  */
  hdac.Instance = DAC;
  if (HAL_DAC_Init(&hdac) != HAL_OK)
  {
    Error_Handler();
  }

  /** DAC channel OUT1 config
  */
  sConfig.DAC_Trigger = DAC_TRIGGER_T2_TRGO;
  sConfig.DAC_OutputBuffer = DAC_OUTPUTBUFFER_ENABLE;
  if (HAL_DAC_ConfigChannel(&hdac, &sConfig, DAC_CHANNEL_1) != HAL_OK)
  {
    Error_Handler();
  }

  /** DAC channel OUT2 config
  */
  if (HAL_DAC_ConfigChannel(&hdac, &sConfig, DAC_CHANNEL_2) != HAL_OK)
  {
    Error_Handler();
  }

}

static void MX_I2C2_Init(void)
{

  hi2c2.Instance = I2C2;
  hi2c2.Init.Timing = 0x00506682;
  hi2c2.Init.OwnAddress1 = 0;
  hi2c2.Init.AddressingMode = I2C_ADDRESSINGMODE_7BIT;
  hi2c2.Init.DualAddressMode = I2C_DUALADDRESS_DISABLE;
  hi2c2.Init.OwnAddress2 = 0;
  hi2c2.Init.OwnAddress2Masks = I2C_OA2_NOMASK;
  hi2c2.Init.GeneralCallMode = I2C_GENERALCALL_DISABLE;
  hi2c2.Init.NoStretchMode = I2C_NOSTRETCH_DISABLE;
  if (HAL_I2C_Init(&hi2c2) != HAL_OK)
  {
    Error_Handler();
  }

  /** Configure Analogue filter
  */
  if (HAL_I2CEx_ConfigAnalogFilter(&hi2c2, I2C_ANALOGFILTER_ENABLE) != HAL_OK)
  {
    Error_Handler();
  }

  /** Configure Digital filter
  */
  if (HAL_I2CEx_ConfigDigitalFilter(&hi2c2, 0) != HAL_OK)
  {
    Error_Handler();
  }

}

static void MX_I2C4_Init(void)
{

  hi2c4.Instance = I2C4;
  hi2c4.Init.Timing = 0x00506682;
  hi2c4.Init.OwnAddress1 = 0;
  hi2c4.Init.AddressingMode = I2C_ADDRESSINGMODE_7BIT;
  hi2c4.Init.DualAddressMode = I2C_DUALADDRESS_DISABLE;
  hi2c4.Init.OwnAddress2 = 0;
  hi2c4.Init.OwnAddress2Masks = I2C_OA2_NOMASK;
  hi2c4.Init.GeneralCallMode = I2C_GENERALCALL_DISABLE;
  hi2c4.Init.NoStretchMode = I2C_NOSTRETCH_DISABLE;
  if (HAL_I2C_Init(&hi2c4) != HAL_OK)
  {
    Error_Handler();
  }

  /** Configure Analogue filter
  */
  if (HAL_I2CEx_ConfigAnalogFilter(&hi2c4, I2C_ANALOGFILTER_ENABLE) != HAL_OK)
  {
    Error_Handler();
  }

  /** Configure Digital filter
  */
  if (HAL_I2CEx_ConfigDigitalFilter(&hi2c4, 0) != HAL_OK)
  {
    Error_Handler();
  }

}

static void MX_SPI4_Init(void)
{

  /* SPI4 parameter configuration*/
  hspi4.Instance = SPI4;
  hspi4.Init.Mode = SPI_MODE_MASTER;
  hspi4.Init.Direction = SPI_DIRECTION_2LINES;
  hspi4.Init.DataSize = SPI_DATASIZE_4BIT;
  hspi4.Init.CLKPolarity = SPI_POLARITY_LOW;
  hspi4.Init.CLKPhase = SPI_PHASE_1EDGE;
  hspi4.Init.NSS = SPI_NSS_SOFT;
  hspi4.Init.BaudRatePrescaler = SPI_BAUDRATEPRESCALER_2;
  hspi4.Init.FirstBit = SPI_FIRSTBIT_MSB;
  hspi4.Init.TIMode = SPI_TIMODE_DISABLE;
  hspi4.Init.CRCCalculation = SPI_CRCCALCULATION_DISABLE;
  hspi4.Init.CRCPolynomial = 7;
  hspi4.Init.CRCLength = SPI_CRC_LENGTH_DATASIZE;
  hspi4.Init.NSSPMode = SPI_NSS_PULSE_ENABLE;
  if (HAL_SPI_Init(&hspi4) != HAL_OK)
  {
    Error_Handler();
  }

}

static void MX_SPI6_Init(void)
{

  /* SPI6 parameter configuration*/
  hspi6.Instance = SPI6;
  hspi6.Init.Mode = SPI_MODE_MASTER;
  hspi6.Init.Direction = SPI_DIRECTION_2LINES;
  hspi6.Init.DataSize = SPI_DATASIZE_4BIT;
  hspi6.Init.CLKPolarity = SPI_POLARITY_LOW;
  hspi6.Init.CLKPhase = SPI_PHASE_1EDGE;
  hspi6.Init.NSS = SPI_NSS_SOFT;
  hspi6.Init.BaudRatePrescaler = SPI_BAUDRATEPRESCALER_2;
  hspi6.Init.FirstBit = SPI_FIRSTBIT_MSB;
  hspi6.Init.TIMode = SPI_TIMODE_DISABLE;
  hspi6.Init.CRCCalculation = SPI_CRCCALCULATION_DISABLE;
  hspi6.Init.CRCPolynomial = 7;
  hspi6.Init.CRCLength = SPI_CRC_LENGTH_DATASIZE;
  hspi6.Init.NSSPMode = SPI_NSS_PULSE_ENABLE;
  if (HAL_SPI_Init(&hspi6) != HAL_OK)
  {
    Error_Handler();
  }

}

static void MX_TIM1_Init(void)
{

  TIM_ClockConfigTypeDef sClockSourceConfig = {0};
  TIM_MasterConfigTypeDef sMasterConfig = {0};

  htim1.Instance = TIM1;
  htim1.Init.Prescaler = 47999;
  htim1.Init.CounterMode = TIM_COUNTERMODE_UP;
  htim1.Init.Period = 999;
  htim1.Init.ClockDivision = TIM_CLOCKDIVISION_DIV1;
  htim1.Init.RepetitionCounter = 0;
  htim1.Init.AutoReloadPreload = TIM_AUTORELOAD_PRELOAD_DISABLE;
  if (HAL_TIM_Base_Init(&htim1) != HAL_OK)
  {
    Error_Handler();
  }
  sClockSourceConfig.ClockSource = TIM_CLOCKSOURCE_INTERNAL;
  if (HAL_TIM_ConfigClockSource(&htim1, &sClockSourceConfig) != HAL_OK)
  {
    Error_Handler();
  }
  sMasterConfig.MasterOutputTrigger = TIM_TRGO_RESET;
  sMasterConfig.MasterOutputTrigger2 = TIM_TRGO2_RESET;
  sMasterConfig.MasterSlaveMode = TIM_MASTERSLAVEMODE_DISABLE;
  if (HAL_TIMEx_MasterConfigSynchronization(&htim1, &sMasterConfig) != HAL_OK)
  {
    Error_Handler();
  }

}

static void MX_TIM2_Init(void)
{

  TIM_ClockConfigTypeDef sClockSourceConfig = {0};
  TIM_MasterConfigTypeDef sMasterConfig = {0};

  htim2.Instance = TIM2;
  htim2.Init.Prescaler = 0;
  htim2.Init.CounterMode = TIM_COUNTERMODE_UP;
  htim2.Init.Period = 479999;
  htim2.Init.ClockDivision = TIM_CLOCKDIVISION_DIV1;
  htim2.Init.AutoReloadPreload = TIM_AUTORELOAD_PRELOAD_DISABLE;
  if (HAL_TIM_Base_Init(&htim2) != HAL_OK)
  {
    Error_Handler();
  }
  sClockSourceConfig.ClockSource = TIM_CLOCKSOURCE_INTERNAL;
  if (HAL_TIM_ConfigClockSource(&htim2, &sClockSourceConfig) != HAL_OK)
  {
    Error_Handler();
  }
  sMasterConfig.MasterOutputTrigger = TIM_TRGO_UPDATE;
  sMasterConfig.MasterSlaveMode = TIM_MASTERSLAVEMODE_DISABLE;
  if (HAL_TIMEx_MasterConfigSynchronization(&htim2, &sMasterConfig) != HAL_OK)
  {
    Error_Handler();
  }
  /* USER CODE BEGIN TIM2_Init 2 */
  if (HAL_TIM_Base_Start_IT(&htim2) != HAL_OK) {
      Error_Handler();
  }
  /* USER CODE END TIM2_Init 2 */

}

static void MX_USART3_UART_Init(void)
{

  huart3.Instance = USART3;
  huart3.Init.BaudRate = 115200;
  huart3.Init.WordLength = UART_WORDLENGTH_8B;
  huart3.Init.StopBits = UART_STOPBITS_1;
  huart3.Init.Parity = UART_PARITY_NONE;
  huart3.Init.Mode = UART_MODE_TX_RX;
  huart3.Init.HwFlowCtl = UART_HWCONTROL_NONE;
  huart3.Init.OverSampling = UART_OVERSAMPLING_16;
  huart3.Init.OneBitSampling = UART_ONE_BIT_SAMPLE_DISABLE;
  huart3.AdvancedInit.AdvFeatureInit = UART_ADVFEATURE_NO_INIT;
  if (HAL_UART_Init(&huart3) != HAL_OK)
  {
    Error_Handler();
  }

}

static void MX_DMA_Init(void)
{

  /* DMA controller clock enable */
  __HAL_RCC_DMA2_CLK_ENABLE();
  __HAL_RCC_DMA1_CLK_ENABLE();

  /* USART3 TX DMA configuration */
  hdma_usart3_tx.Instance = DMA1_Stream3;
  hdma_usart3_tx.Init.Channel = DMA_CHANNEL_4;
  hdma_usart3_tx.Init.Direction = DMA_MEMORY_TO_PERIPH;
  hdma_usart3_tx.Init.PeriphInc = DMA_PINC_DISABLE;
  hdma_usart3_tx.Init.MemInc = DMA_MINC_ENABLE;
  hdma_usart3_tx.Init.PeriphDataAlignment = DMA_PDATAALIGN_BYTE;
  hdma_usart3_tx.Init.MemDataAlignment = DMA_MDATAALIGN_BYTE;
  hdma_usart3_tx.Init.Mode = DMA_NORMAL;
  hdma_usart3_tx.Init.Priority = DMA_PRIORITY_LOW;
  hdma_usart3_tx.Init.FIFOMode = DMA_FIFOMODE_DISABLE;
  if (HAL_DMA_Init(&hdma_usart3_tx) != HAL_OK)
  {
    Error_Handler();
  }
  __HAL_LINKDMA(&huart3, hdmatx, hdma_usart3_tx);

  /* DMA interrupt init */
  /* DMA1_Stream5_IRQn interrupt configuration */
  HAL_NVIC_SetPriority(DMA1_Stream5_IRQn, 5, 0);
  HAL_NVIC_EnableIRQ(DMA1_Stream5_IRQn);
  /* DMA1_Stream6_IRQn interrupt configuration */
  HAL_NVIC_SetPriority(DMA1_Stream6_IRQn, 5, 0);
  HAL_NVIC_EnableIRQ(DMA1_Stream6_IRQn);
  /* DMA1_Stream3_IRQn interrupt configuration */
  HAL_NVIC_SetPriority(DMA1_Stream3_IRQn, 5, 0);
  HAL_NVIC_EnableIRQ(DMA1_Stream3_IRQn);
  /* DMA2_Stream0_IRQn interrupt configuration */
  HAL_NVIC_SetPriority(DMA2_Stream0_IRQn, 5, 0);
  HAL_NVIC_EnableIRQ(DMA2_Stream0_IRQn);
  /* DMA2_Stream1_IRQn interrupt configuration */
  HAL_NVIC_SetPriority(DMA2_Stream1_IRQn, 5, 0);
  HAL_NVIC_EnableIRQ(DMA2_Stream1_IRQn);
  /* DMA2_Stream2_IRQn interrupt configuration */
  HAL_NVIC_SetPriority(DMA2_Stream2_IRQn, 5, 0);
  HAL_NVIC_EnableIRQ(DMA2_Stream2_IRQn);

}

static void MX_GPIO_Init(void)
{
  GPIO_InitTypeDef GPIO_InitStruct = {0};

  /* GPIO Ports Clock Enable */
  __HAL_RCC_GPIOE_CLK_ENABLE();
  __HAL_RCC_GPIOC_CLK_ENABLE();
  __HAL_RCC_GPIOF_CLK_ENABLE();
  __HAL_RCC_GPIOH_CLK_ENABLE();
  __HAL_RCC_GPIOA_CLK_ENABLE();
  __HAL_RCC_GPIOB_CLK_ENABLE();
  __HAL_RCC_GPIOG_CLK_ENABLE();
  __HAL_RCC_GPIOD_CLK_ENABLE();

  /*Configure GPIO pin Output Level */
  HAL_GPIO_WritePin(GPIOF, GPIO_PIN_12|GPIO_PIN_13, GPIO_PIN_RESET);

  /*Configure GPIO pin Output Level */
  HAL_GPIO_WritePin(GPIOE, GPIO_PIN_7|GPIO_PIN_8|GPIO_PIN_9|GPIO_PIN_11
                          |GPIO_PIN_13, GPIO_PIN_RESET);

  /*Configure GPIO pin Output Level */
  HAL_GPIO_WritePin(GPIOD, GPIO_PIN_14|GPIO_PIN_15, GPIO_PIN_RESET);

  /*Configure GPIO pin Output Level */
  HAL_GPIO_WritePin(GPIOG, GPIO_PIN_9, GPIO_PIN_RESET);

  /*Configure GPIO pin Output Level */
  HAL_GPIO_WritePin(LD2_GPIO_Port, LD2_Pin, GPIO_PIN_RESET);

  /*Configure GPIO pins : PE3 PE4 PE10 PE12
                           PE14 PE15 PE0 PE1 */
  GPIO_InitStruct.Pin = GPIO_PIN_3|GPIO_PIN_4|GPIO_PIN_10|GPIO_PIN_12
                          |GPIO_PIN_14|GPIO_PIN_15|GPIO_PIN_0|GPIO_PIN_1;
  GPIO_InitStruct.Mode = GPIO_MODE_ANALOG;
  GPIO_InitStruct.Pull = GPIO_NOPULL;
  HAL_GPIO_Init(GPIOE, &GPIO_InitStruct);

  /*Configure GPIO pin : USER_Btn_Pin */
  GPIO_InitStruct.Pin = USER_Btn_Pin;
  GPIO_InitStruct.Mode = GPIO_MODE_IT_RISING;
  GPIO_InitStruct.Pull = GPIO_NOPULL;
  HAL_GPIO_Init(USER_Btn_GPIO_Port, &GPIO_InitStruct);

  /*Configure GPIO pins : PF2 PF11 */
  GPIO_InitStruct.Pin = GPIO_PIN_2|GPIO_PIN_11;
  GPIO_InitStruct.Mode = GPIO_MODE_ANALOG;
  GPIO_InitStruct.Pull = GPIO_NOPULL;
  HAL_GPIO_Init(GPIOF, &GPIO_InitStruct);

  /*Configure GPIO pins : PB2 PB10 PB11 PB12
                           PB14 PB15 PB4 PB6 */
  GPIO_InitStruct.Pin = GPIO_PIN_2|GPIO_PIN_10|GPIO_PIN_11|GPIO_PIN_12
                          |GPIO_PIN_14|GPIO_PIN_15|GPIO_PIN_4|GPIO_PIN_6;
  GPIO_InitStruct.Mode = GPIO_MODE_ANALOG;
  GPIO_InitStruct.Pull = GPIO_NOPULL;
  HAL_GPIO_Init(GPIOB, &GPIO_InitStruct);

  /*Configure GPIO pins : PF12 PF13 */
  GPIO_InitStruct.Pin = GPIO_PIN_12|GPIO_PIN_13;
  GPIO_InitStruct.Mode = GPIO_MODE_OUTPUT_PP;
  GPIO_InitStruct.Pull = GPIO_NOPULL;
  GPIO_InitStruct.Speed = GPIO_SPEED_FREQ_LOW;
  HAL_GPIO_Init(GPIOF, &GPIO_InitStruct);

  /*Configure GPIO pins : PG0 PG1 PG2 PG3
                           PG4 PG5 PG6 PG8
                           PG10 PG11 PG15 */
  GPIO_InitStruct.Pin = GPIO_PIN_0|GPIO_PIN_1|GPIO_PIN_2|GPIO_PIN_3
                          |GPIO_PIN_4|GPIO_PIN_5|GPIO_PIN_6|GPIO_PIN_8
                          |GPIO_PIN_10|GPIO_PIN_11|GPIO_PIN_15;
  GPIO_InitStruct.Mode = GPIO_MODE_ANALOG;
  GPIO_InitStruct.Pull = GPIO_NOPULL;
  HAL_GPIO_Init(GPIOG, &GPIO_InitStruct);

  /*Configure GPIO pins : PE7 PE8 PE9 PE11
                           PE13 */
  GPIO_InitStruct.Pin = GPIO_PIN_7|GPIO_PIN_8|GPIO_PIN_9|GPIO_PIN_11
                          |GPIO_PIN_13;
  GPIO_InitStruct.Mode = GPIO_MODE_OUTPUT_PP;
  GPIO_InitStruct.Pull = GPIO_NOPULL;
  GPIO_InitStruct.Speed = GPIO_SPEED_FREQ_LOW;
  HAL_GPIO_Init(GPIOE, &GPIO_InitStruct);

  /*Configure GPIO pins : PD10 PD11 PD12 PD13
                           PD3 PD4 PD5 PD6
                           PD7 */
  GPIO_InitStruct.Pin = GPIO_PIN_10|GPIO_PIN_11|GPIO_PIN_12|GPIO_PIN_13
                          |GPIO_PIN_3|GPIO_PIN_4|GPIO_PIN_5|GPIO_PIN_6
                          |GPIO_PIN_7;
  GPIO_InitStruct.Mode = GPIO_MODE_ANALOG;
  GPIO_InitStruct.Pull = GPIO_NOPULL;
  HAL_GPIO_Init(GPIOD, &GPIO_InitStruct);

  /*Configure GPIO pins : PD14 PD15 */
  GPIO_InitStruct.Pin = GPIO_PIN_14|GPIO_PIN_15;
  GPIO_InitStruct.Mode = GPIO_MODE_OUTPUT_PP;
  GPIO_InitStruct.Pull = GPIO_NOPULL;
  GPIO_InitStruct.Speed = GPIO_SPEED_FREQ_LOW;
  HAL_GPIO_Init(GPIOD, &GPIO_InitStruct);

  /*Configure GPIO pin : USB_OverCurrent_Pin */
  GPIO_InitStruct.Pin = USB_OverCurrent_Pin;
  GPIO_InitStruct.Mode = GPIO_MODE_INPUT;
  GPIO_InitStruct.Pull = GPIO_NOPULL;
  HAL_GPIO_Init(USB_OverCurrent_GPIO_Port, &GPIO_InitStruct);

  /*Configure GPIO pins : PC6 PC7 PC8 PC9
                           PC10 PC11 PC12 */
  GPIO_InitStruct.Pin = GPIO_PIN_6|GPIO_PIN_7|GPIO_PIN_8|GPIO_PIN_9
                          |GPIO_PIN_10|GPIO_PIN_11|GPIO_PIN_12;
  GPIO_InitStruct.Mode = GPIO_MODE_AF_PP;
  GPIO_InitStruct.Pull = GPIO_NOPULL;
  GPIO_InitStruct.Speed = GPIO_SPEED_FREQ_VERY_HIGH;
  GPIO_InitStruct.Alternate = GPIO_AF12_SDMMC1;
  HAL_GPIO_Init(GPIOC, &GPIO_InitStruct);

  /*Configure GPIO pin : PA10 */
  GPIO_InitStruct.Pin = GPIO_PIN_10;
  GPIO_InitStruct.Mode = GPIO_MODE_ANALOG;
  GPIO_InitStruct.Pull = GPIO_NOPULL;
  HAL_GPIO_Init(GPIOA, &GPIO_InitStruct);

  /*Configure GPIO pin : PD2 */
  GPIO_InitStruct.Pin = GPIO_PIN_2;
  GPIO_InitStruct.Mode = GPIO_MODE_AF_PP;
  GPIO_InitStruct.Pull = GPIO_NOPULL;
  GPIO_InitStruct.Speed = GPIO_SPEED_FREQ_VERY_HIGH;
  GPIO_InitStruct.Alternate = GPIO_AF12_SDMMC1;
  HAL_GPIO_Init(GPIOD, &GPIO_InitStruct);

  /*Configure GPIO pin : PG9 */
  GPIO_InitStruct.Pin = GPIO_PIN_9;
  GPIO_InitStruct.Mode = GPIO_MODE_OUTPUT_PP;
  GPIO_InitStruct.Pull = GPIO_NOPULL;
  GPIO_InitStruct.Speed = GPIO_SPEED_FREQ_LOW;
  HAL_GPIO_Init(GPIOG, &GPIO_InitStruct);

  /*Configure GPIO pin : LD2_Pin */
  GPIO_InitStruct.Pin = LD2_Pin;
  GPIO_InitStruct.Mode = GPIO_MODE_OUTPUT_PP;
  GPIO_InitStruct.Pull = GPIO_NOPULL;
  GPIO_InitStruct.Speed = GPIO_SPEED_FREQ_LOW;
  HAL_GPIO_Init(LD2_GPIO_Port, &GPIO_InitStruct);

  /*Configure GPIO pins : PB8 PB9 */
  GPIO_InitStruct.Pin = GPIO_PIN_8|GPIO_PIN_9;
  GPIO_InitStruct.Mode = GPIO_MODE_AF_PP;
  GPIO_InitStruct.Pull = GPIO_NOPULL;
  GPIO_InitStruct.Speed = GPIO_SPEED_FREQ_VERY_HIGH;
  GPIO_InitStruct.Alternate = GPIO_AF12_SDMMC1;
  HAL_GPIO_Init(GPIOB, &GPIO_InitStruct);

}

/* USER CODE BEGIN 4 */
// Override the _write function to reroute printf to USART3
int _write(int file, char *data, int len)
{
    // Transmit data using the non-blocking UART DMA queue.
    // This keeps printf from blocking the scheduler.
    if (sendMessageRaw(data, len) > 0) {
        return len;
    }

    return 0;
}

int telemetryUpdateableCallback(Updateable* self)
{
    (void)self;
    processTelemetryConfigRequests();
    processTelemetrySignals();
    return 0;
}

#endif // <--- DONT DELETE THIS, IT IS LINKED TO LAST LINE IN MAIN FUNCTION TO ALLOW SIL BUILDS

/* FreeRTOS hooks */
void vApplicationMallocFailedHook(void) {
    //printf("ERROR: FreeRTOS malloc failed!\n");
    for(;;);
}

void vApplicationIdleHook(void) {
    // Called when no tasks are running
    // Can enter low power mode here
}

void vApplicationStackOverflowHook(TaskHandle_t xTask, char *pcTaskName) {
    //printf("ERROR: Stack overflow in task: %s\n", pcTaskName);
    for(;;);
}

void vApplicationTickHook(void) {
    // Called on each FreeRTOS tick (optional)
    // Keep this very short and fast
}

/**
 * @brief Enhanced CAN message handler for Inverter system
 * @param system Pointer to the Inverter system
 * @param message Received CAN message with parsed signals
 */
//void inverter_can_handler(void* system, CAN_Message* message) {
//    Inverter* inverter = (Inverter*)system;
//
//    // Log the received message for debugging
//    sendMessage("INVERTER_CAN", MSG_DEBUG, "ReceivedMsg=%s;ID=0x%lX;DLC=%lu",
//               message->template->name, message->header.StdId, message->header.DLC);
//
//    // Store complete message data based on message ID using DBC structures
//    if (message->header.StdId == ESC_MOTOR_STATUS_1_ID) {
//        // Parse ESC Motor Status 1 message
//        ESC_Motor_Status_1_t* status1 = &inverter->can_data.status1;
//
//        for (int i = 0; i < message->template->signal_count; i++) {
//            CAN_Signal* signal = &message->signals[i];
//
//            if (strcmp(signal->template->name, "Motor_Speed") == 0) {
//                status1->motor_speed = (uint16_t)signal->value;
//                inverter->can_data.new_data_flags |= INVERTER_NEW_SPEED;
//            } else if (strcmp(signal->template->name, "Motor_Torque") == 0) {
//                status1->motor_torque = (int16_t)signal->value;
//                inverter->can_data.new_data_flags |= INVERTER_NEW_TORQUE;
//            } else if (strcmp(signal->template->name, "Motor_Temperature") == 0) {
//                status1->motor_temperature = (uint8_t)signal->value;
//                inverter->can_data.new_data_flags |= INVERTER_NEW_TEMP;
//            } else if (strcmp(signal->template->name, "Motor_Fault_Status") == 0) {
//                status1->motor_fault_status = (uint8_t)signal->value;
//            }
//        }
//
//    } else if (message->header.StdId == ESC_MOTOR_STATUS_2_ID) {
//        // Parse ESC Motor Status 2 message
//        ESC_Motor_Status_2_t* status2 = &inverter->can_data.status2;
//
//        for (int i = 0; i < message->template->signal_count; i++) {
//            CAN_Signal* signal = &message->signals[i];
//
//            if (strcmp(signal->template->name, "Motor_Voltage") == 0) {
//                status2->motor_voltage = (uint16_t)signal->value;
//                inverter->can_data.new_data_flags |= INVERTER_NEW_VOLTAGE;
//            } else if (strcmp(signal->template->name, "Motor_Current") == 0) {
//                status2->motor_current = (int16_t)signal->value;
//                inverter->can_data.new_data_flags |= INVERTER_NEW_CURRENT;
//            } else if (strcmp(signal->template->name, "Motor_Power") == 0) {
//                status2->motor_power = (uint16_t)signal->value;
//            } else if (strcmp(signal->template->name, "ESC_Temperature") == 0) {
//                status2->esc_temperature = (uint8_t)signal->value;
//            }
//        }
//    }
//
//    // Send telemetry for all signals (with proper physical values)
//    for (int i = 0; i < message->template->signal_count; i++) {
//        CAN_Signal* signal = &message->signals[i];
//
//        // Calculate physical value using DBC scaling
//        float physical_value = signal->value * signal->template->scale + signal->template->offset;
//
//        sendMessage("INVERTER_DATA", MSG_SENSOR_VALUE, "Signal=%s;Value=%f;Unit=%s",
//                   signal->template->name, physical_value, signal->template->unit);
//    }
//
//    // Update metadata
//    inverter->can_data.last_update = HAL_GetTick();
//    inverter->can_data.message_count++;
//
//    // Note: Data will be processed in updateInverter() which runs in main loop context
//}

/**
 * @brief Test function to send inverter CAN messages for testing
 * Call this function to simulate receiving inverter status messages
 */
void send_test_inverter_messages(void) {
    static int test_counter = 0;
    test_counter++;

    // Test Message 1: ESC Motor Status 1 (ID: 0x102)
    // Speed: 2000 + test_counter RPM, Torque: 50.5 Nm, Temp: 60°C
    uint8_t motor_status_1[8];
    uint16_t speed = 2000 + (test_counter * 10); // Increasing speed
    motor_status_1[0] = speed & 0xFF;
    motor_status_1[1] = (speed >> 8) & 0xFF;

    int16_t torque = 505; // 50.5 Nm * 10
    motor_status_1[2] = torque & 0xFF;
    motor_status_1[3] = (torque >> 8) & 0xFF;

    motor_status_1[4] = 100; // 60°C + 40
    motor_status_1[5] = 0;   // No fault
    motor_status_1[6] = 0;
    motor_status_1[7] = 0;

    // Send via CAN1
    send_CAN_message(CAN_1, CAN_2A, 0x102, motor_status_1, 8);

    sendMessage("TEST", MSG_DEBUG, "SentTestMsg=ESC_Motor_Status_1;Speed=%d;Torque=50.5", speed);

    // Test Message 2: ESC Motor Status 2 (ID: 0x103)
    // Voltage: 48.0V, Current: 12.5A, Power: 2.5kW, ESC Temp: 45°C
    uint8_t motor_status_2[8];
    uint16_t voltage = 480; // 48.0V * 10
    motor_status_2[0] = voltage & 0xFF;
    motor_status_2[1] = (voltage >> 8) & 0xFF;

    int16_t current = 125; // 12.5A * 10
    motor_status_2[2] = current & 0xFF;
    motor_status_2[3] = (current >> 8) & 0xFF;

    uint16_t power = 25; // 2.5kW * 10
    motor_status_2[4] = power & 0xFF;
    motor_status_2[5] = (power >> 8) & 0xFF;

    motor_status_2[6] = 85; // 45°C + 40
    motor_status_2[7] = 0;

    // Send via CAN1
    send_CAN_message(CAN_1, CAN_2A, 0x103, motor_status_2, 8);

    sendMessage("TEST", MSG_DEBUG, "SentTestMsg=ESC_Motor_Status_2;Voltage=48.0;Current=12.5");
}

/* USER CODE END 4 */

void StartDefaultTask(void *argument)
{
  /* init code for USB_DEVICE */
  MX_USB_DEVICE_Init();
  /* USER CODE BEGIN 5 */
  /* Infinite loop */
  for(;;)
  {
    processTelemetryConfigRequests();
    processTelemetrySignals();
    osDelay(10);
  }
  /* USER CODE END 5 */
}

void Error_Handler(void)
{
  /* USER CODE BEGIN Error_Handler_Debug */
  /* User can add his own implementation to report the HAL error return state */

  #ifndef TEST_MODE
  __disable_irq();
  #endif

  while (1)
  {
    //printf("Error_Handler\r\n");
  }
  /* USER CODE END Error_Handler_Debug */
}

#ifdef  USE_FULL_ASSERT
/**
  * @brief  Reports the name of the source file and the source line number
  *         where the assert_param error has occurred.
  * @param  file: pointer to the source file name
  * @param  line: assert_param error line source number
  * @retval None
  */
void assert_failed(uint8_t *file, uint32_t line)
{
  /* USER CODE BEGIN 6 */
  /* User can add his own implementation to report the file name and line number,
     ex: //printf("Wrong parameters value: file %s on line %d\r\n", file, line) */
  /* USER CODE END 6 */
}
#endif /* USE_FULL_ASSERT */
